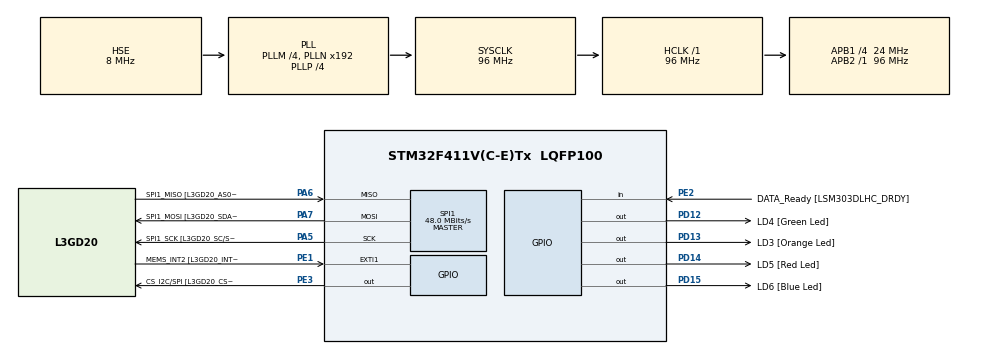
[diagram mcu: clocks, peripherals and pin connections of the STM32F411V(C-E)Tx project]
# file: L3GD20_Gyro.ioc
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Mcu.Family=STM32F4
Mcu.Name=STM32F411V(C-E)Tx
Mcu.Package=LQFP100
NVIC.PriorityGroup=NVIC_PRIORITYGROUP_0
PA13.GPIO_Label=SWDIO
PA13.Mode=Serial_Wire
PA13.Signal=SYS_JTMS-SWDIO
PA14.GPIO_Label=SWCLK
PA14.Mode=Serial_Wire
PA14.Signal=SYS_JTCK-SWCLK
PA5.GPIO_Label=SPI1_SCK [L3GD20_SC/SPC]
PA5.Mode=Full_Duplex_Master
PA5.Signal=SPI1_SCK
PA6.GPIO_Label=SPI1_MISO [L3GD20_AS0/SDO]
PA6.Mode=Full_Duplex_Master
PA6.Signal=SPI1_MISO
PA7.GPIO_Label=SPI1_MOSI [L3GD20_SDA/SDI/SDO]
PA7.Mode=Full_Duplex_Master
PA7.Signal=SPI1_MOSI
PD12.GPIO_Label=LD4 [Green Led]
PD12.GPIO_PuPd=GPIO_NOPULL
PD12.GPIO_Speed=GPIO_SPEED_FREQ_LOW
PD12.Signal=GPIO_Output
PD13.GPIO_Label=LD3 [Orange Led]
PD13.GPIO_PuPd=GPIO_NOPULL
PD13.GPIO_Speed=GPIO_SPEED_FREQ_LOW
PD13.Signal=GPIO_Output
PD14.GPIO_Label=LD5 [Red Led]
PD14.GPIO_PuPd=GPIO_NOPULL
PD14.GPIO_Speed=GPIO_SPEED_FREQ_LOW
PD14.Signal=GPIO_Output
PD15.GPIO_Label=LD6 [Blue Led]
PD15.GPIO_PuPd=GPIO_NOPULL
PD15.GPIO_Speed=GPIO_SPEED_FREQ_LOW
PD15.Signal=GPIO_Output
PE1.GPIO_Label=MEMS_INT2 [L3GD20_INT2]
PE1.GPIO_ModeDefaultEXTI=GPIO_MODE_EVT_RISING
PE1.Signal=GPXTI1
PE2.GPIO_Label=DATA_Ready [LSM303DLHC_DRDY]
PE2.Signal=GPIO_Input
PE3.GPIO_Label=CS_I2C/SPI [L3GD20_CS_I2C/SPI]
PE3.Signal=GPIO_Output
PH0\ -\ OSC_IN.Mode=HSE-External-Oscillator
PH0\ -\ OSC_IN.Signal=RCC_OSC_IN
PH1\ -\ OSC_OUT.Mode=HSE-External-Oscillator
PH1\ -\ OSC_OUT.Signal=RCC_OSC_OUT
ProjectManager.HeapSize=0x200
ProjectManager.StackSize=0x400
ProjectManager.TargetToolchain=STM32CubeIDE
RCC.48MHZClocksFreq_Value=48000000
RCC.AHBFreq_Value=96000000
RCC.APB1CLKDivider=RCC_HCLK_DIV4
RCC.APB1Freq_Value=24000000
RCC.APB1TimFreq_Value=48000000
RCC.APB2Freq_Value=96000000
RCC.APB2TimFreq_Value=96000000
RCC.CortexFreq_Value=96000000
RCC.HCLKFreq_Value=96000000
RCC.HSE_VALUE=8000000
RCC.HSI_VALUE=16000000
RCC.LSE_VALUE=32768
RCC.PLLI2SM=5
RCC.PLLI2SN=200
RCC.PLLM=4
RCC.PLLP=RCC_PLLP_DIV4
RCC.PLLQ=8
RCC.PLLSourceVirtual=RCC_PLLSOURCE_HSE
RCC.SYSCLKFreq_VALUE=96000000
RCC.SYSCLKSource=RCC_SYSCLKSOURCE_PLLCLK
RCC.VCOOutputFreq_Value=384000000
SPI1.BaudRatePrescaler=SPI_BAUDRATEPRESCALER_2
SPI1.CalculateBaudRate=48.0 MBits/s
SPI1.Direction=SPI_DIRECTION_2LINES
SPI1.Mode=SPI_MODE_MASTER
SPI1.VirtualType=VM_MASTER
board=STM32F411E-DISCO

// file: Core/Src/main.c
/* USER CODE BEGIN Header */
/**
  ******************************************************************************
  * @file           : main.c
  * @brief          : Main program body
  ******************************************************************************
  * @attention
  *
  * Copyright (c) 2023 STMicroelectronics.
  * All rights reserved.
  *
  * This software is licensed under terms that can be found in the LICENSE file
  * in the root directory of this software component.
  * If no LICENSE file comes with this software, it is provided AS-IS.
  *
  ******************************************************************************
  */
/* USER CODE END Header */
#include "main.h"

/* USER CODE BEGIN Includes */
#include "L3GD20.h"
#include <stdio.h>
/* USER CODE END Includes */

SPI_HandleTypeDef hspi1;

void SystemClock_Config(void);
static void MX_GPIO_Init(void);
static void MX_SPI1_Init(void);
/* USER CODE BEGIN PFP */

float angle , gyrox, gyroz , gyroy;
float dt;
double current_time, prev_time;

/* USER CODE END PFP */

int main(void)
{

  /* MCU Configuration--------------------------------------------------------*/

  /* Reset of all peripherals, Initializes the Flash interface and the Systick. */
  HAL_Init();

  /* Configure the system clock */
  SystemClock_Config();

  /* Initialize all configured peripherals */
  MX_GPIO_Init();
  MX_SPI1_Init();
  /* USER CODE BEGIN 2 */
HAL_SPI_Init(&hspi1);
L3GD20_Init(FS_2000dps);
  /* USER CODE END 2 */

  /* Infinite loop */
  while (1)
  {

    /* USER CODE BEGIN 3 */

	  angle = (angle + gyrox * dt);
//	 prev_time = HAL_GetTick();
	 // printf("Açı = %f \n" ,gyrox);
	  gyrox = Gyro_Read_X();
	  gyroz = Gyro_Read_Z();
	  gyroy = Gyro_Read_Y();

	 HAL_Delay(50);
	// current_time = HAL_GetTick();
	  dt = 0.05;

  }
  /* USER CODE END 3 */
}

void SystemClock_Config(void)
{
  RCC_OscInitTypeDef RCC_OscInitStruct = {0};
  RCC_ClkInitTypeDef RCC_ClkInitStruct = {0};

  /** Configure the main internal regulator output voltage
  */
  __HAL_RCC_PWR_CLK_ENABLE();
  __HAL_PWR_VOLTAGESCALING_CONFIG(PWR_REGULATOR_VOLTAGE_SCALE1);

  /** Initializes the RCC Oscillators according to the specified parameters
  * in the RCC_OscInitTypeDef structure.
  */
  RCC_OscInitStruct.OscillatorType = RCC_OSCILLATORTYPE_HSE;
  RCC_OscInitStruct.HSEState = RCC_HSE_ON;
  RCC_OscInitStruct.PLL.PLLState = RCC_PLL_ON;
  RCC_OscInitStruct.PLL.PLLSource = RCC_PLLSOURCE_HSE;
  RCC_OscInitStruct.PLL.PLLM = 4;
  RCC_OscInitStruct.PLL.PLLN = 192;
  RCC_OscInitStruct.PLL.PLLP = RCC_PLLP_DIV4;
  RCC_OscInitStruct.PLL.PLLQ = 8;
  if (HAL_RCC_OscConfig(&RCC_OscInitStruct) != HAL_OK)
  {
    Error_Handler();
  }

  /** Initializes the CPU, AHB and APB buses clocks
  */
  RCC_ClkInitStruct.ClockType = RCC_CLOCKTYPE_HCLK|RCC_CLOCKTYPE_SYSCLK
                              |RCC_CLOCKTYPE_PCLK1|RCC_CLOCKTYPE_PCLK2;
  RCC_ClkInitStruct.SYSCLKSource = RCC_SYSCLKSOURCE_PLLCLK;
  RCC_ClkInitStruct.AHBCLKDivider = RCC_SYSCLK_DIV1;
  RCC_ClkInitStruct.APB1CLKDivider = RCC_HCLK_DIV4;
  RCC_ClkInitStruct.APB2CLKDivider = RCC_HCLK_DIV1;

  if (HAL_RCC_ClockConfig(&RCC_ClkInitStruct, FLASH_LATENCY_3) != HAL_OK)
  {
    Error_Handler();
  }
}

static void MX_SPI1_Init(void)
{

  /* SPI1 parameter configuration*/
  hspi1.Instance = SPI1;
  hspi1.Init.Mode = SPI_MODE_MASTER;
  hspi1.Init.Direction = SPI_DIRECTION_2LINES;
  hspi1.Init.DataSize = SPI_DATASIZE_8BIT;
  hspi1.Init.CLKPolarity = SPI_POLARITY_LOW;
  hspi1.Init.CLKPhase = SPI_PHASE_1EDGE;
  hspi1.Init.NSS = SPI_NSS_SOFT;
  hspi1.Init.BaudRatePrescaler = SPI_BAUDRATEPRESCALER_2;
  hspi1.Init.FirstBit = SPI_FIRSTBIT_MSB;
  hspi1.Init.TIMode = SPI_TIMODE_DISABLE;
  hspi1.Init.CRCCalculation = SPI_CRCCALCULATION_DISABLE;
  hspi1.Init.CRCPolynomial = 10;
  if (HAL_SPI_Init(&hspi1) != HAL_OK)
  {
    Error_Handler();
  }

}

static void MX_GPIO_Init(void)
{
  GPIO_InitTypeDef GPIO_InitStruct = {0};

  /* GPIO Ports Clock Enable */
  __HAL_RCC_GPIOE_CLK_ENABLE();
  __HAL_RCC_GPIOH_CLK_ENABLE();
  __HAL_RCC_GPIOA_CLK_ENABLE();
  __HAL_RCC_GPIOD_CLK_ENABLE();

  /*Configure GPIO pin Output Level */
  HAL_GPIO_WritePin(CS_I2C_SPI_GPIO_Port, CS_I2C_SPI_Pin, GPIO_PIN_RESET);

  /*Configure GPIO pin Output Level */
  HAL_GPIO_WritePin(GPIOD, LD4_Pin|LD3_Pin|LD5_Pin|LD6_Pin, GPIO_PIN_RESET);

  /*Configure GPIO pin : DATA_Ready_Pin */
  GPIO_InitStruct.Pin = DATA_Ready_Pin;
  GPIO_InitStruct.Mode = GPIO_MODE_INPUT;
  GPIO_InitStruct.Pull = GPIO_NOPULL;
  HAL_GPIO_Init(DATA_Ready_GPIO_Port, &GPIO_InitStruct);

  /*Configure GPIO pin : CS_I2C_SPI_Pin */
  GPIO_InitStruct.Pin = CS_I2C_SPI_Pin;
  GPIO_InitStruct.Mode = GPIO_MODE_OUTPUT_PP;
  GPIO_InitStruct.Pull = GPIO_NOPULL;
  GPIO_InitStruct.Speed = GPIO_SPEED_FREQ_LOW;
  HAL_GPIO_Init(CS_I2C_SPI_GPIO_Port, &GPIO_InitStruct);

  /*Configure GPIO pins : LD4_Pin LD3_Pin LD5_Pin LD6_Pin */
  GPIO_InitStruct.Pin = LD4_Pin|LD3_Pin|LD5_Pin|LD6_Pin;
  GPIO_InitStruct.Mode = GPIO_MODE_OUTPUT_PP;
  GPIO_InitStruct.Pull = GPIO_NOPULL;
  GPIO_InitStruct.Speed = GPIO_SPEED_FREQ_LOW;
  HAL_GPIO_Init(GPIOD, &GPIO_InitStruct);

  /*Configure GPIO pin : MEMS_INT2_Pin */
  GPIO_InitStruct.Pin = MEMS_INT2_Pin;
  GPIO_InitStruct.Mode = GPIO_MODE_EVT_RISING;
  GPIO_InitStruct.Pull = GPIO_NOPULL;
  HAL_GPIO_Init(MEMS_INT2_GPIO_Port, &GPIO_InitStruct);

}

void Error_Handler(void)
{
  __disable_irq();
  while (1)
  {
  }
}
